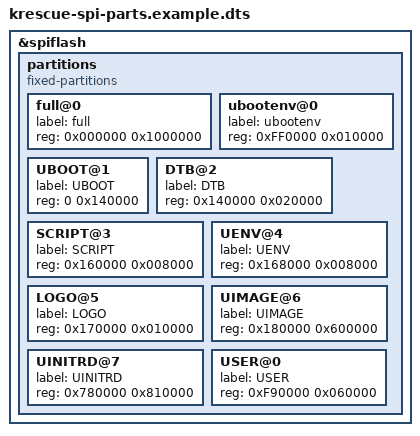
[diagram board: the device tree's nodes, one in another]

// 

&spiflash {

    partitions {
    compatible = "fixed-partitions";
    #address-cells = <1>;
    #size-cells = <1>;

    full@0 {
        label = "full";
        reg = <0x000000 0x1000000>;
    };

    ubootenv@0 {
        label = "ubootenv";
        reg = <0xFF0000 0x010000>;
    };



    UBOOT@1 {
        label = "UBOOT";
        reg = <0 0x140000>;
    };
    

    DTB@2 {
        label = "DTB";
        reg = <0x140000 0x020000>;
    };
    

    SCRIPT@3 {
        label = "SCRIPT";
        reg = <0x160000 0x008000>;
    };
    

    UENV@4 {
        label = "UENV";
        reg = <0x168000 0x008000>;
    };
    

    LOGO@5 {
        label = "LOGO";
        reg = <0x170000 0x010000>;
    };
    

    UIMAGE@6 {
        label = "UIMAGE";
        reg = <0x180000 0x600000>;
    };
    

    UINITRD@7 {
        label = "UINITRD";
        reg = <0x780000 0x810000>;
    };
    

    USER@0 {
        label = "USER";
        reg = <0xF90000 0x060000>;
    };

    };
};

